# LPC82x register map
Vendor: nxp.com; File version: 1.0
CPU: CM0PLUS r0p0, little endian, no MPU, no FPU, VTOR, 2 interrupt priority bits
Registers are 32-bit, read-write, reset 0x0 unless marked. A register's access mark holds for its fields unless they carry their own. Offsets are from the block's base; [hi:lo] are bit positions; {n}, {i} and the like mark numbered series; 'fields as' and 'values as' point back to an identical list.

## SYSCON — LPC82x System configuration (SYSCON)
Base 0x40048000
0x00 SYSMEMREMAP — System Remap register
  [1:0] MAP — System memory remap. Value 0x3 is reserved.
    0=BOOT_LOADER_MODE (Boot Loader Mode. Interrupt vectors are re-mapped to Boot ROM.); 1=USER_RAM_MODE (User RAM Mode. Interrupt vectors are re-mapped to Static RAM.); 2=USER_FLASH_MODE (User Flash Mode. Interrupt vectors are not re-mapped and reside in Flash.)
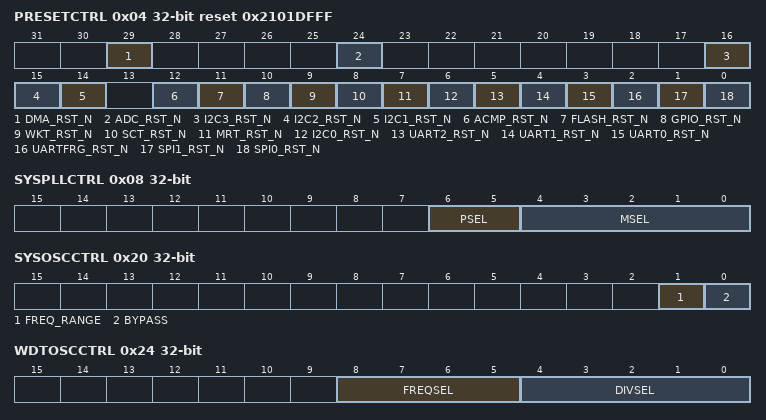
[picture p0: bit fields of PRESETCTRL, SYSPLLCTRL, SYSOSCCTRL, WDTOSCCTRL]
0x04 PRESETCTRL reset 0x2101DFFF — Peripheral reset control register
  [29] DMA_RST_N — DMA reset control.
    0=Assert the DMA reset; 1=Clear the DMA reset
  [24] ADC_RST_N — ADC reset control.
    0=Assert the ADC reset; 1=Clear the ADC reset
  [16] I2C3_RST_N — I2C3 reset control.
    0=Assert the I2C3 reset; 1=Clear the I2C3 reset
  [15] I2C2_RST_N — I2C2 reset control.
    0=Assert the I2C2 reset; 1=Clear the I2C2 reset
  [14] I2C1_RST_N — I2C1 reset control.
    0=Assert the I2C1 reset; 1=Clear the I2C1 reset
  [12] ACMP_RST_N — Analog comparator reset control.
    0=Assert the analog comparator reset; 1=Clear the analog comparator controller reset
  [11] FLASH_RST_N — Flash controller reset control.
    0=Assert the flash controller reset; 1=Clear the flash controller reset
  [10] GPIO_RST_N — GPIO and GPIO pin interrupt reset control.
    0=Assert the GPIO reset; 1=Clear the GPIO reset
  [9] WKT_RST_N — Self-wake-up timer (WKT) reset control.
    0=Assert the WKT reset; 1=Clear the WKT reset
  [8] SCT_RST_N — SCT reset control.
    0=Assert the SCT reset; 1=Clear the SCT reset
  [7] MRT_RST_N — Multi-rate timer (MRT) reset control.
    0=Assert the MRT reset; 1=Clear the MRT reset
  [6] I2C0_RST_N — I2C0 reset control.
    0=Assert the I2C0 reset; 1=Clear the I2C0 reset
  [5] UART2_RST_N — USART2 reset control.
    0=Assert the USART2 reset; 1=Clear the USART2 reset
  [4] UART1_RST_N — USART1 reset control.
    0=Assert the USART1 reset; 1=Clear the USART1 reset
  [3] UART0_RST_N — USART0 reset control.
    0=Assert the USART0 reset; 1=Clear the USART0 reset
  [2] UARTFRG_RST_N — USART fractional baud rate generator(UARTFRG) reset control.
    0=Assert the UARTFRG reset; 1=Clear the UARTFRG reset
  [1] SPI1_RST_N — SPI1 reset control.
    0=Assert the SPI1 reset; 1=Clear the SPI1 reset
  [0] SPI0_RST_N — SPI0 reset control.
    0=Assert the SPI0 reset; 1=Clear the SPI0 reset
0x08 SYSPLLCTRL — PLL control
  [6:5] PSEL — Post divider ratio P. The division ratio is 2 x P.
    0=P = 1; 1=P = 2; 2=P = 4; 3=P = 8
  [4:0] MSEL — Feedback divider value. The division value M is the programmed MSEL value + 1. 00000: Division ratio M = 1 to 11111: Division ratio M = 32
0x0C SYSPLLSTAT ro — PLL status
  [0] LOCK — PLL0 lock indicator
0x20 SYSOSCCTRL — system oscillator control
  [1] FREQ_RANGE — oscillator low / high transconductance selection input (Active High) 1-20MHz '0' : 15-50MHz '1'
  [0] BYPASS — Bypass system oscillator
0x24 WDTOSCCTRL — Watchdog oscillator control
  [8:5] FREQSEL — Frequency select. Selects the frequency of the oscillator. 0x00 = invalid setting when watchdog oscillator is running 0x1 = 0.6 MHz 0x2 = 1.05 MHz 0x3 = 1.4 MHz 0x4 = 1.75 MHz 0x5 = 2.1 MHz 0x6 = 2.4 MHz 0x7 = 2.7 MHz 0x8 = 3.0 MHz 0x9 = 3.25 MHz 0xA = 3.5 MHz 0xB = 3.75 MHz 0xC = 4.0 MHz 0xD = 4.2 MHz 0xE = 4.4 MHz 0xF = 4.6 MHz
  [4:0] DIVSEL — Select divider for Fclkana. wdt_osc_clk = Fclkana/ (2 x (1 + DIVSEL)) 00000: 2 x (1 + DIVSEL) = 2 00001: 2 x (1 + DIVSEL) = 4 to 11111: 2 x (1 + DIVSEL) = 64
0x28 IRCCTRL reset 0x80 — IRC control
  [7:0] TRIM — Trim value
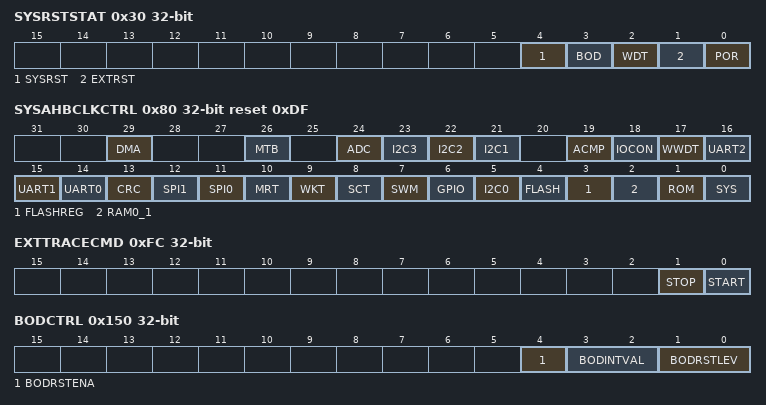
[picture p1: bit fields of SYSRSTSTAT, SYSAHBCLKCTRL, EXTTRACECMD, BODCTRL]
0x30 SYSRSTSTAT — System reset status register
  [4] SYSRST — Status of the software system reset.
    0=No System reset detected; 1=System reset detected. Writing a one clears this reset.
  [3] BOD — Status of the Brown-out detect reset.
    0=No BOD reset detected; 1=BOD reset detected. Writing a one clears this reset.
  [2] WDT — Status of the Watchdog reset.
    0=No WDT reset detected; 1=WDT reset detected. Writing a one clears this reset.
  [1] EXTRST — Status of the external RESET pin. External reset status.
    0=No reset event detected; 1=Reset detected. Writing a one clears this reset.
  [0] POR — POR reset status.
    0=No POR detected; 1=POR detected. Writing a one clears this reset.
0x40 SYSPLLCLKSEL — System PLL clock source select register
  [1:0] SEL — System PLL clock source
    0=IRC; 1=SYSOSC (Crystal Oscillator (SYSOSC)); 3=CLKIN (CLKIN. External clock input.)
0x44 SYSPLLCLKUEN — System PLL clock source update enable register
  [0] ENA — Enable system PLL clock source update
    0=NO_CHANGE; 1=UPDATED (update clock source)
0x70 MAINCLKSEL — Main clock source select
  [1:0] SEL — Clock source for main clock.
    0=IRC Oscillator; 1=PLL input; 2=WDTOSC (Watchdog oscillator.); 3=PLL output
0x74 MAINCLKUEN — Main clock source update enable
  [0] ENA — Enable main clock source update.
    0=No change; 1=Update clock source
0x78 SYSAHBCLKDIV reset 0x1 — System clock divider
  [7:0] DIV — System AHB clock divider values 0: System clock disabled. 1: Divide by 1. to 255: Divide by 255.
0x80 SYSAHBCLKCTRL reset 0xDF — System clock control
  [29] DMA — Enables clock to DMA.
    0=Disable; 1=Enable
  [26] MTB — Enables clock to micro-trace buffer control registers.Turn on this clock when using the micro-trace buffer for debug purposes.
    0=Disable; 1=Enable
  [24] ADC — Enables clock to ADC.
    0=Disable; 1=Enable
  [23] I2C3 — Enables clock to I2C3.
    0=Disable; 1=Enable
  [22] I2C2 — Enables clock to I2C2.
    0=Disable; 1=Enable
  [21] I2C1 — Enables clock to I2C1.
    0=Disable; 1=Enable
  [19] ACMP — Enables clock to analog comparator.
    0=Disable; 1=Enable
  [18] IOCON — Enables clock for IOCON block.
    0=Disable; 1=Enable
  [17] WWDT — Enables clock for WWDT.
    0=Disable; 1=Enable
  [16] UART2 — Enables clock for USART2.
    0=Disable; 1=Enable
  [15] UART1 — Enables clock for USART1.
    0=Disable; 1=Enable
  [14] UART0 — Enables clock for USART0.
    0=Disable; 1=Enable
  [13] CRC — Enables clock for CRC.
    0=Disable; 1=Enable
  [12] SPI1 — Enables clock for SPI1.
    0=Disable; 1=Enable
  [11] SPI0 — Enables clock for SPI0.
    0=Disable; 1=Enable
  [10] MRT — Enables clock for multi-rate timer.
    0=Disable; 1=Enable
  [9] WKT — Enables clock for self-wake-up timer.
    0=Disable; 1=Enable
  [8] SCT — Enables clock for state configurable timer SCTimer/PWM.
    0=Disable; 1=Enable
  [7] SWM — Enables clock for switch matrix.
    0=Disable; 1=Enable
  [6] GPIO — Enables clock for GPIO port registers and GPIO pin interrupt registers.
    0=Disable; 1=Enable
  [5] I2C0 — Enables clock for I2C0.
    0=Disable; 1=Enable
  [4] FLASH — Enables clock for flash.
    0=Disable; 1=Enable
  [3] FLASHREG — Enables clock for flash register interface.
    0=Disable; 1=Enable
  [2] RAM0_1 — Enables clock for SRAM0 and SRAM1.
    0=Disable; 1=Enable
  [1] ROM — Enables clock for ROM.
    0=Disable; 1=Enable
  [0] SYS — Enables the clock for the AHB, the APB bridge, the Cortex-M0+ core clocks, SYSCON, and the PMU. This bit is read only and always reads as 1.
0x94 UARTCLKDIV — USART clock divider
  [7:0] DIV — USART fractional baud rate generator clock divider values. 0: Clock disabled. 1: Divide by 1. to 255: Divide by 255.
0xE0 CLKOUTSEL — CLKOUT clock source select
  [1:0] SEL — CLKOUT clock source.
    0=IRC oscillator; 1=SYSOSC (Crystal oscillator (SYSOSC)); 2=WDTOSC (Watchdog oscillator); 3=MAIN_CLK (Main clock)
0xE4 CLKOUTUEN — CLKOUT clock source update enable
  [0] ENA — Enable CLKOUT clock source update.
    0=No change; 1=Update clock source
0xE8 CLKOUTDIV — PLL control
  [7:0] DIV — CLKOUT clock divider values. 0: Disable CLKOUT clock divider 1: Divide by 1 to 255: Divide by 255
0xF0 UARTFRGDIV — USART1 to USART4 common fractional generator divider value
  [7:0] DIV — Denominator of the fractional divider. DIV is equal to the programmed value +1. Always set to 0xFF to use with the fractional baud rate generator.
0xF4 UARTFRGMULT — USART common fractional generator divider value
  [7:0] MULT — Numerator of the fractional divider. MULT is equal to the programmed value.
0xFC EXTTRACECMD — External trace buffer command register
  [1] STOP — Trace stop command. Writing a one to this bit sets the TSTOP signal in the MTB to HIGH and stops tracing if the TSTOPEN bit in the MTB master register is set to one as well.
  [0] START — Trace start command. Writing a one to this bit sets the TSTART signal to the MTB to HIGH and starts tracing if the TSTARTEN bit in the MTB master register is set to one as well.
0x100 PIOPORCAP0 reset not defined — POR captured PIO status 0
  [17:0] PIOSTAT ro — State of PIO0_17 through PIO0_0 at power-on reset
0x134 IOCONCLKDIV6 — Peripheral clock 6 to the IOCON block for programmable glitch filter
  [7:0] DIV — IOCON glitch filter clock divider values 0: Disable IOCONFILTR_PCLK. 1: Divide by 1. to 255: Divide by 255.
0x138 IOCONCLKDIV5 — Peripheral clock 6 to the IOCON block for programmable glitch filter
  fields as IOCONCLKDIV6
0x13C IOCONCLKDIV4 — Peripheral clock 4 to the IOCON block for programmable glitch filter
  fields as IOCONCLKDIV6
0x140 IOCONCLKDIV3 — Peripheral clock 3 to the IOCON block for programmable glitch filter
  fields as IOCONCLKDIV6
0x144 IOCONCLKDIV2 — Peripheral clock 2 to the IOCON block for programmable glitch filter
  fields as IOCONCLKDIV6
0x148 IOCONCLKDIV1 — Peripheral clock 1 to the IOCON block for programmable glitch filter
  fields as IOCONCLKDIV6
0x14C IOCONCLKDIV0 — Peripheral clock 0 to the IOCON block for programmable glitch filter
  fields as IOCONCLKDIV6
0x150 BODCTRL — BOD control register
  [4] BODRSTENA — BOD reset enable
    0=DISABLE (Disable reset function.); 1=ENABLE (Enable reset function.)
  [3:2] BODINTVAL — BOD interrupt level
    1=LEVEL_1; 2=LEVEL_2; 3=LEVEL_3
  [1:0] BODRSTLEV — BOD reset level
    1=LEVEL_1; 2=LEVEL_2; 3=LEVEL_3
0x154 SYSTCKCAL — System tick timer calibration register
  [25:0] CAL — System tick timer calibration value.
0x170 IRQLATENCY reset 0x10
  [7:0] LATENCY — 8-bit latency value.
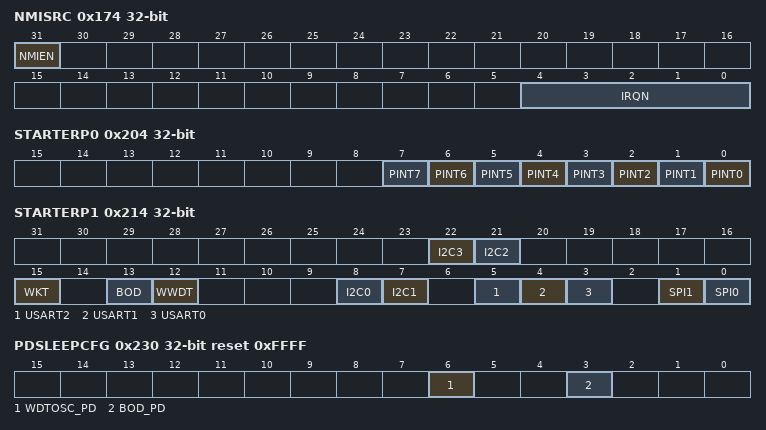
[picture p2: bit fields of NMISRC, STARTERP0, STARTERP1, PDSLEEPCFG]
0x174 NMISRC — NMI source selection register
  [31] NMIEN — Write a 1 to this bit to enable the Non-Maskable Interrupt (NMI) source selected by bits 4:0.
  [4:0] IRQN — The IRQ number of the interrupt that acts as the Non-Maskable Interrupt (NMI) if bit 31 is 1
{0x178+4i} PINTSEL[{i}] (i=0..7) — Pin interrupt select registers N
  [5:0] INTPIN — Pin number select for pin interrupt or pattern match engine input. (PIO0_0 to PIO0_28 correspond to numbers 0 to 28).
0x204 STARTERP0 — Start logic 0 pin wake-up enable register 0
  [all] fields
    0=DISABLED; 1=ENABLED
  [n] PINT{n} (n=0..7) — GPIO pin interrupt {n} wake-up
0x214 STARTERP1 (reset mask 0xFF) — Start logic 0 pin wake-up enable register 1
  [all] fields
    0=DISABLED; 1=ENABLED
  [22] I2C3 — I2C3 interrupt wake-up
  [21] I2C2 — I2C2 interrupt wake-up
  [15] WKT — Self-wake-up timer interrupt wake-up
  [13] BOD — BOD interrupt wake-up
  [12] WWDT — WWDT interrupt wake-up
  [8] I2C0 — I2C0 interrupt wake-up.
  [7] I2C1 — I2C1 interrupt wake-up.
  [5] USART2 — USART2 interrupt wake-up. Configure USART in synchronous slave mode.
  [4] USART1 — USART1 interrupt wake-up. Configure USART in synchronous slave mode.
  [3] USART0 — USART0 interrupt wake-up. Configure USART in synchronous slave mode.
  [1] SPI1 — SPI1 interrupt wake-up
  [0] SPI0 — SPI0 interrupt wake-up
0x230 PDSLEEPCFG reset 0xFFFF — Deep-sleep configuration register
  [6] WDTOSC_PD — Watchdog oscillator power-down control for Deep-sleep and Power-down mode. Changing this bit to powered-down has no effect when the LOCK bit in the WWDT MOD register is set. In this case, the watchdog oscillator is always running.
    0=DISABLED; 1=ENABLED
  [3] BOD_PD — BOD power-down control for Deep-sleep and Power-down mode
    0=POWERED; 1=POWERED_DOWN
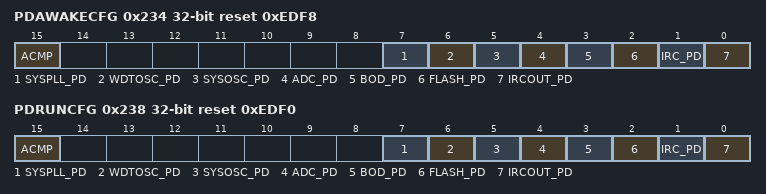
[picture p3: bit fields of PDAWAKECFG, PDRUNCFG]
0x234 PDAWAKECFG reset 0xEDF8 — Wake-up configuration register
  [15] ACMP — Analog comparator wake-up configuration
    0=DISABLED; 1=ENABLED
  [7] SYSPLL_PD — System PLL wake-up configuration
    0=DISABLED; 1=ENABLED
  [6] WDTOSC_PD — Watchdog oscillator wake-up configuration. Changing this bit to powered-down has no effect when the LOCK bit in the WWDT MOD register is set. In this case, the watchdog oscillator is always running
    0=DISABLED; 1=ENABLED
  [5] SYSOSC_PD — Crystal oscillator wake-up configuration
    0=POWERED; 1=POWERED_DOWN
  [4] ADC_PD — ADC wake-up configuration
    0=POWERED; 1=POWERED_DOWN
  [3] BOD_PD — BOD wake-up configuration
    0=POWERED; 1=POWERED_DOWN
  [2] FLASH_PD — Flash wake-up configuration
    0=POWERED; 1=POWERED_DOWN
  [1] IRC_PD — IRC oscillator power-down wake-up configuration
    0=POWERED; 1=POWERED_DOWN
  [0] IRCOUT_PD — IRC oscillator output wake-up configuration
    0=POWERED; 1=POWERED_DOWN
0x238 PDRUNCFG reset 0xEDF0 — Power configuration register
  fields as PDAWAKECFG
0x3F8 DEVICE_ID ro — Part ID register
  [31:0] DEVICEID — Part ID
